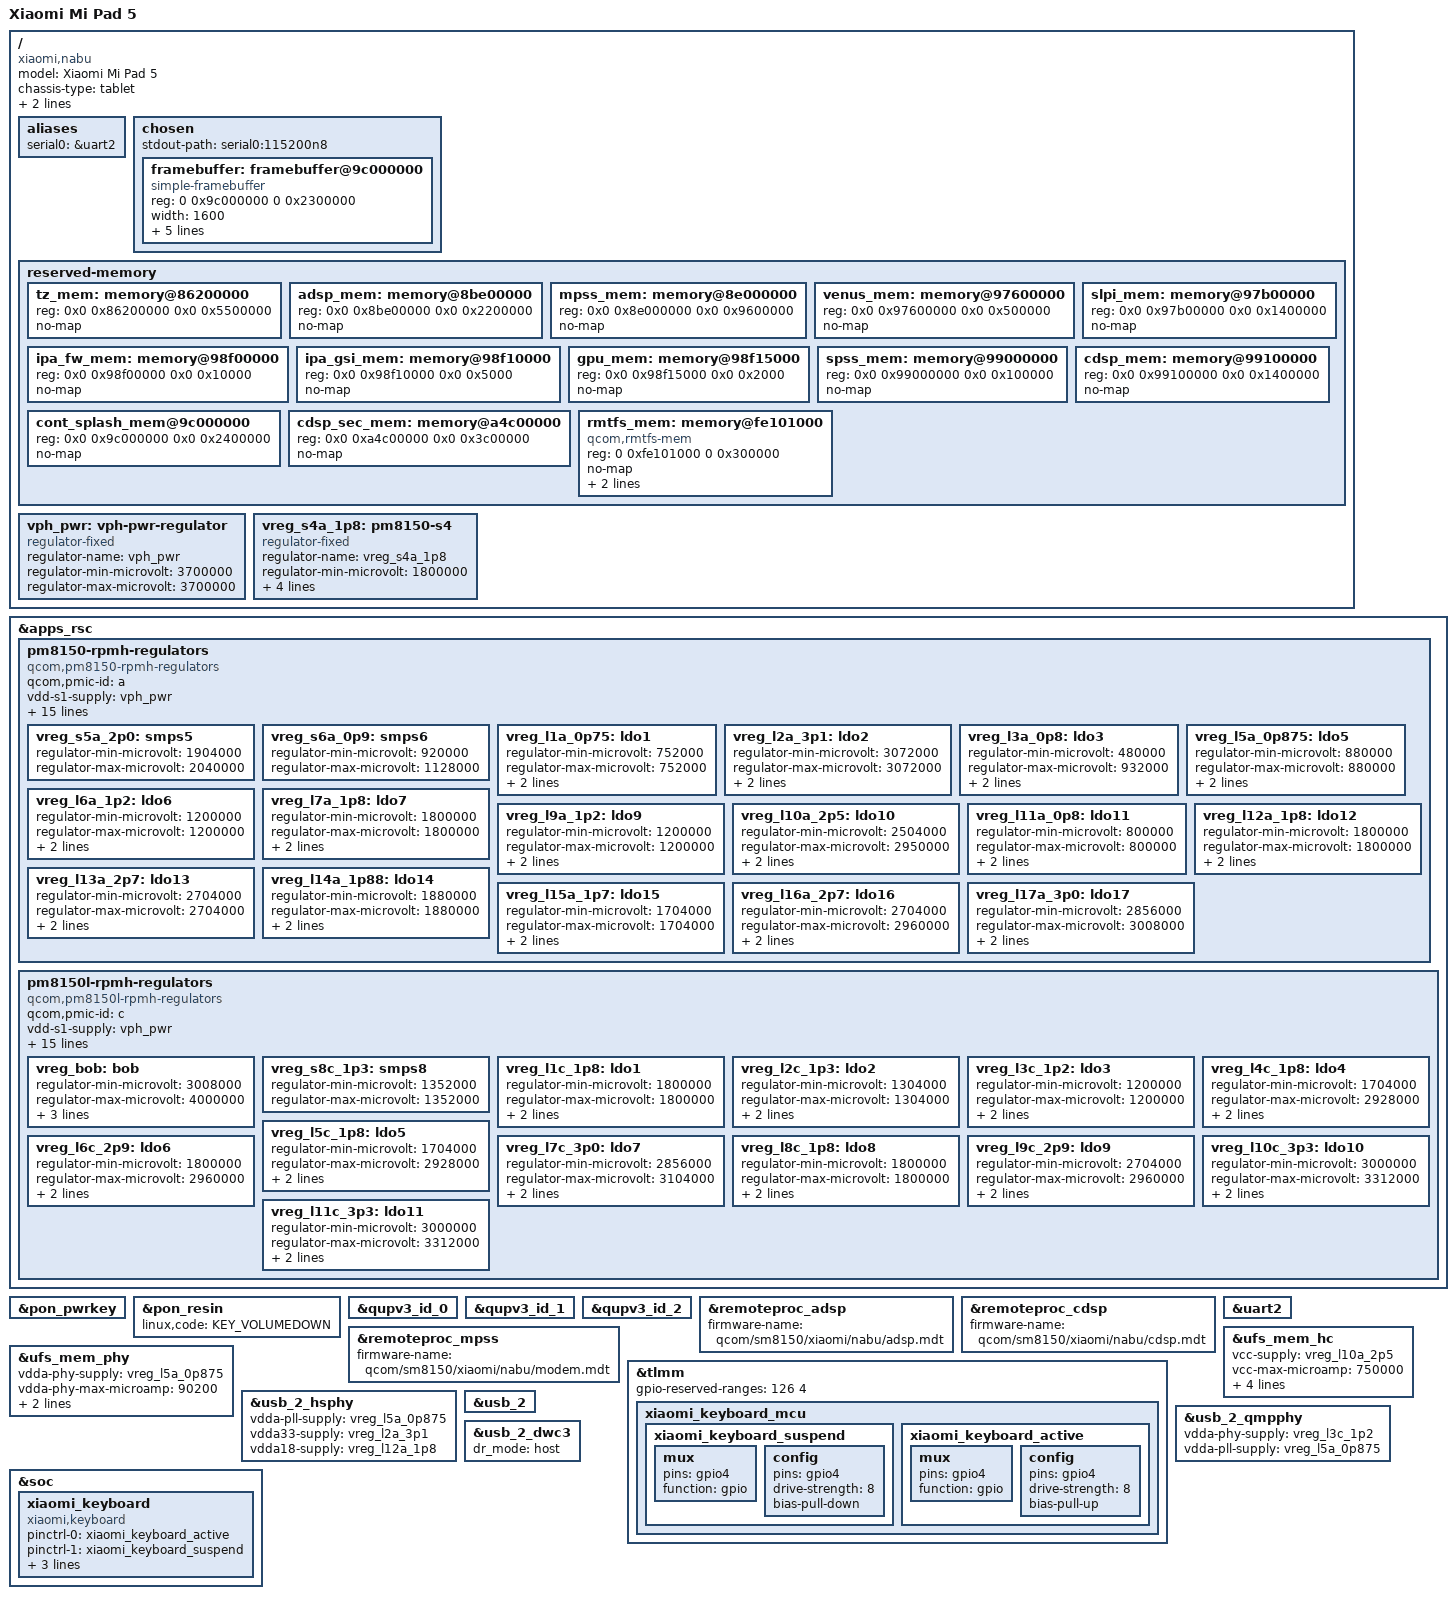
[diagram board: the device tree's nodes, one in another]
// SPDX-License-Identifier: BSD-3-Clause
/*
 * Copyright (c) 2017-2019, The Linux Foundation. All rights reserved.
 * Copyright (c) 2019, Linaro Limited
 */

/dts-v1/;

#include <dt-bindings/regulator/qcom,rpmh-regulator.h>
#include <dt-bindings/gpio/gpio.h>
#include <dt-bindings/usb/pd.h>
#include <dt-bindings/phy/phy.h>
#include "sm8150.dtsi"
#include "pm8150.dtsi"
#include "pm8150b.dtsi"
#include "pm8150l.dtsi"

/delete-node/ &tz_mem;
/delete-node/ &cdsp_mem;
/delete-node/ &gpu_mem;
/delete-node/ &ipa_fw_mem;
/delete-node/ &ipa_gsi_mem;
/delete-node/ &adsp_mem;
/delete-node/ &mpss_mem;
/delete-node/ &slpi_mem;
/delete-node/ &spss_mem;
/delete-node/ &venus_mem;
/delete-node/ &rmtfs_mem;
/*
 * delete node mdss and dispcc if
 * use simple-framebuffer
 */
/delete-node/ &mdss;
/delete-node/ &dispcc;

/ {
	model = "Xiaomi Mi Pad 5";
	compatible = "xiaomi,nabu", "qcom,sm8150";
	chassis-type = "tablet";
	qcom,msm-id = <339 0x20000>;
	qcom,board-id = <48 0>;

	aliases {
		serial0 = &uart2;
	};

	chosen {
		#address-cells = <2>;
		#size-cells = <2>;
		ranges;

		stdout-path = "serial0:115200n8";

		framebuffer: framebuffer@9c000000 {
		compatible = "simple-framebuffer";
			reg = <0 0x9c000000 0 0x2300000>;
			width = <1600>;
			height = <2560>;
			stride = <(1600 * 4)>;
			format = "a8r8g8b8";
			/*
			* That's (going to be) a lot of clocks, but it's necessary due
			* to unused clk cleanup & no panel driver yet (& no dispcc either)..
			*/
			clocks = <&gcc GCC_DISP_HF_AXI_CLK>,
					<&gcc GCC_DISP_SF_AXI_CLK>;
		};
	};

	reserved-memory {
		#address-cells = <2>;
		#size-cells = <2>;
		ranges;

		tz_mem: memory@86200000 {
			reg = <0x0 0x86200000 0x0 0x5500000>;
			no-map;
		};

		adsp_mem: memory@8be00000 {
			reg = <0x0 0x8be00000 0x0 0x2200000>;
			no-map;
		};

		mpss_mem: memory@8e000000 {
			reg = <0x0 0x8e000000 0x0 0x9600000>;
			no-map;
		};

		venus_mem: memory@97600000 {
			reg = <0x0 0x97600000 0x0 0x500000>;
			no-map;
		};

		slpi_mem: memory@97b00000 {
			reg = <0x0 0x97b00000 0x0 0x1400000>;
			no-map;
		};

		ipa_fw_mem: memory@98f00000 {
			reg = <0x0 0x98f00000 0x0 0x10000>;
			no-map;
		};

		ipa_gsi_mem: memory@98f10000 {
			reg = <0x0 0x98f10000 0x0 0x5000>;
			no-map;
		};

		gpu_mem: memory@98f15000 {
			reg = <0x0 0x98f15000 0x0 0x2000>;
			no-map;
		};

		spss_mem: memory@99000000 {
			reg = <0x0 0x99000000 0x0 0x100000>;
			no-map;
		};

		cdsp_mem: memory@99100000 {
			reg = <0x0 0x99100000 0x0 0x1400000>;
			no-map;
		};

		cont_splash_mem@9c000000 {
			reg = <0x0 0x9c000000 0x0 0x2400000>;
			no-map;
		};

		cdsp_sec_mem: memory@a4c00000 {
			reg = <0x0 0xa4c00000 0x0 0x3c00000>;
			no-map;
		};

		rmtfs_mem: memory@fe101000 {
			compatible = "qcom,rmtfs-mem";
			reg = <0 0xfe101000 0 0x300000>;
			no-map;

			qcom,client-id = <1>;
			qcom,vmid = <15>;
		};
	};

	vph_pwr: vph-pwr-regulator {
		compatible = "regulator-fixed";
		regulator-name = "vph_pwr";
		regulator-min-microvolt = <3700000>;
		regulator-max-microvolt = <3700000>;
	};

	/*
	 * Apparently RPMh does not provide support for PM8150 S4 because it
	 * is always-on; model it as a fixed regulator.
	 */
	vreg_s4a_1p8: pm8150-s4 {
		compatible = "regulator-fixed";
		regulator-name = "vreg_s4a_1p8";

		regulator-min-microvolt = <1800000>;
		regulator-max-microvolt = <1800000>;

		regulator-always-on;
		regulator-boot-on;

		vin-supply = <&vph_pwr>;
	};
};

&apps_rsc {
	pm8150-rpmh-regulators {
		compatible = "qcom,pm8150-rpmh-regulators";
		qcom,pmic-id = "a";

		vdd-s1-supply = <&vph_pwr>;
		vdd-s2-supply = <&vph_pwr>;
		vdd-s3-supply = <&vph_pwr>;
		vdd-s4-supply = <&vph_pwr>;
		vdd-s5-supply = <&vph_pwr>;
		vdd-s6-supply = <&vph_pwr>;
		vdd-s7-supply = <&vph_pwr>;
		vdd-s8-supply = <&vph_pwr>;
		vdd-s9-supply = <&vph_pwr>;
		vdd-s10-supply = <&vph_pwr>;

		vdd-l1-l8-l11-supply = <&vreg_s6a_0p9>;
		vdd-l2-l10-supply = <&vreg_bob>;
		vdd-l3-l4-l5-l18-supply = <&vreg_s6a_0p9>;
		vdd-l6-l9-supply = <&vreg_s8c_1p3>;
		vdd-l7-l12-l14-l15-supply = <&vreg_s5a_2p0>;
		vdd-l13-l16-l17-supply = <&vreg_bob>;

		vreg_s5a_2p0: smps5 {
			regulator-min-microvolt = <1904000>;
			regulator-max-microvolt = <2040000>;
		};

		vreg_s6a_0p9: smps6 {
			regulator-min-microvolt = <920000>;
			regulator-max-microvolt = <1128000>;
		};

		vreg_l1a_0p75: ldo1 {
			regulator-min-microvolt = <752000>;
			regulator-max-microvolt = <752000>;
			regulator-initial-mode = <RPMH_REGULATOR_MODE_HPM>;
		};

		vreg_l2a_3p1: ldo2 {
			regulator-min-microvolt = <3072000>;
			regulator-max-microvolt = <3072000>;
			regulator-initial-mode = <RPMH_REGULATOR_MODE_HPM>;
		};

		vreg_l3a_0p8: ldo3 {
			regulator-min-microvolt = <480000>;
			regulator-max-microvolt = <932000>;
			regulator-initial-mode = <RPMH_REGULATOR_MODE_HPM>;
		};

		vreg_l5a_0p875: ldo5 {
			regulator-min-microvolt = <880000>;
			regulator-max-microvolt = <880000>;
			regulator-initial-mode = <RPMH_REGULATOR_MODE_HPM>;
		};

		vreg_l6a_1p2: ldo6 {
			regulator-min-microvolt = <1200000>;
			regulator-max-microvolt = <1200000>;
			regulator-initial-mode = <RPMH_REGULATOR_MODE_HPM>;
		};

		vreg_l7a_1p8: ldo7 {
			regulator-min-microvolt = <1800000>;
			regulator-max-microvolt = <1800000>;
			regulator-initial-mode = <RPMH_REGULATOR_MODE_HPM>;
		};

		vreg_l9a_1p2: ldo9 {
			regulator-min-microvolt = <1200000>;
			regulator-max-microvolt = <1200000>;
			regulator-initial-mode = <RPMH_REGULATOR_MODE_HPM>;
		};

		vreg_l10a_2p5: ldo10 {
			regulator-min-microvolt = <2504000>;
			regulator-max-microvolt = <2950000>;
			regulator-initial-mode = <RPMH_REGULATOR_MODE_HPM>;
		};

		vreg_l11a_0p8: ldo11 {
			regulator-min-microvolt = <800000>;
			regulator-max-microvolt = <800000>;
			regulator-initial-mode = <RPMH_REGULATOR_MODE_HPM>;
		};

		vreg_l12a_1p8: ldo12 {
			regulator-min-microvolt = <1800000>;
			regulator-max-microvolt = <1800000>;
			regulator-initial-mode = <RPMH_REGULATOR_MODE_HPM>;
		};

		vreg_l13a_2p7: ldo13 {
			regulator-min-microvolt = <2704000>;
			regulator-max-microvolt = <2704000>;
			regulator-initial-mode = <RPMH_REGULATOR_MODE_HPM>;
		};

		vreg_l14a_1p88: ldo14 {
			regulator-min-microvolt = <1880000>;
			regulator-max-microvolt = <1880000>;
			regulator-initial-mode = <RPMH_REGULATOR_MODE_HPM>;
		};

		vreg_l15a_1p7: ldo15 {
			regulator-min-microvolt = <1704000>;
			regulator-max-microvolt = <1704000>;
			regulator-initial-mode = <RPMH_REGULATOR_MODE_HPM>;
		};

		vreg_l16a_2p7: ldo16 {
			regulator-min-microvolt = <2704000>;
			regulator-max-microvolt = <2960000>;
			regulator-initial-mode = <RPMH_REGULATOR_MODE_HPM>;
		};

		vreg_l17a_3p0: ldo17 {
			regulator-min-microvolt = <2856000>;
			regulator-max-microvolt = <3008000>;
			regulator-initial-mode = <RPMH_REGULATOR_MODE_HPM>;
		};
	};

	pm8150l-rpmh-regulators {
		compatible = "qcom,pm8150l-rpmh-regulators";
		qcom,pmic-id = "c";

		vdd-s1-supply = <&vph_pwr>;
		vdd-s2-supply = <&vph_pwr>;
		vdd-s3-supply = <&vph_pwr>;
		vdd-s4-supply = <&vph_pwr>;
		vdd-s5-supply = <&vph_pwr>;
		vdd-s6-supply = <&vph_pwr>;
		vdd-s7-supply = <&vph_pwr>;
		vdd-s8-supply = <&vph_pwr>;

		vdd-l1-l8-supply = <&vreg_s4a_1p8>;
		vdd-l2-l3-supply = <&vreg_s8c_1p3>;
		vdd-l4-l5-l6-supply = <&vreg_bob>;
		vdd-l7-l11-supply = <&vreg_bob>;
		vdd-l9-l10-supply = <&vreg_bob>;

		vdd-bob-supply = <&vph_pwr>;
		vdd-flash-supply = <&vreg_bob>;
		vdd-rgb-supply = <&vreg_bob>;

		vreg_bob: bob {
			regulator-min-microvolt = <3008000>;
			regulator-max-microvolt = <4000000>;
			regulator-initial-mode = <RPMH_REGULATOR_MODE_AUTO>;
			regulator-allow-bypass;
		};

		vreg_s8c_1p3: smps8 {
			regulator-min-microvolt = <1352000>;
			regulator-max-microvolt = <1352000>;
		};

		vreg_l1c_1p8: ldo1 {
			regulator-min-microvolt = <1800000>;
			regulator-max-microvolt = <1800000>;
			regulator-initial-mode = <RPMH_REGULATOR_MODE_HPM>;
		};

		vreg_l2c_1p3: ldo2 {
			regulator-min-microvolt = <1304000>;
			regulator-max-microvolt = <1304000>;
			regulator-initial-mode = <RPMH_REGULATOR_MODE_HPM>;
		};

		vreg_l3c_1p2: ldo3 {
			regulator-min-microvolt = <1200000>;
			regulator-max-microvolt = <1200000>;
			regulator-initial-mode = <RPMH_REGULATOR_MODE_HPM>;
		};

		vreg_l4c_1p8: ldo4 {
			regulator-min-microvolt = <1704000>;
			regulator-max-microvolt = <2928000>;
			regulator-initial-mode = <RPMH_REGULATOR_MODE_HPM>;
		};

		vreg_l5c_1p8: ldo5 {
			regulator-min-microvolt = <1704000>;
			regulator-max-microvolt = <2928000>;
			regulator-initial-mode = <RPMH_REGULATOR_MODE_HPM>;
		};

		vreg_l6c_2p9: ldo6 {
			regulator-min-microvolt = <1800000>;
			regulator-max-microvolt = <2960000>;
			regulator-initial-mode = <RPMH_REGULATOR_MODE_HPM>;
		};

		vreg_l7c_3p0: ldo7 {
			regulator-min-microvolt = <2856000>;
			regulator-max-microvolt = <3104000>;
			regulator-initial-mode = <RPMH_REGULATOR_MODE_HPM>;
		};

		vreg_l8c_1p8: ldo8 {
			regulator-min-microvolt = <1800000>;
			regulator-max-microvolt = <1800000>;
			regulator-initial-mode = <RPMH_REGULATOR_MODE_HPM>;
		};

		vreg_l9c_2p9: ldo9 {
			regulator-min-microvolt = <2704000>;
			regulator-max-microvolt = <2960000>;
			regulator-initial-mode = <RPMH_REGULATOR_MODE_HPM>;
		};

		vreg_l10c_3p3: ldo10 {
			regulator-min-microvolt = <3000000>;
			regulator-max-microvolt = <3312000>;
			regulator-initial-mode = <RPMH_REGULATOR_MODE_HPM>;
		};

		vreg_l11c_3p3: ldo11 {
			regulator-min-microvolt = <3000000>;
			regulator-max-microvolt = <3312000>;
			regulator-initial-mode = <RPMH_REGULATOR_MODE_HPM>;
		};
	};

	/* PM8009 is not present on these boards, even if downstream sources suggest so. */
};

&pon_pwrkey {
	status = "okay";
};

&pon_resin {
	status = "okay";

	linux,code = <KEY_VOLUMEDOWN>;
};

&qupv3_id_0 {
	status = "okay";
};

&qupv3_id_1 {
	status = "okay";
};

&qupv3_id_2 {
	status = "okay";
};

&remoteproc_adsp {
	status = "okay";
	firmware-name = "qcom/sm8150/xiaomi/nabu/adsp.mdt";
};

&remoteproc_cdsp {
	status = "okay";
	firmware-name = "qcom/sm8150/xiaomi/nabu/cdsp.mdt";
};

&remoteproc_mpss {
	status = "okay";
	firmware-name = "qcom/sm8150/xiaomi/nabu/modem.mdt";
};

&tlmm {
	gpio-reserved-ranges = <126 4>;

	xiaomi_keyboard_mcu {
		xiaomi_keyboard_suspend: xiaomi_keyboard_suspend {
			mux {
				pins = "gpio4";
				function = "gpio";
			};

			config {
				pins = "gpio4";
				drive-strength = <8>;
				bias-pull-down;
			};
		};

		xiaomi_keyboard_active: xiaomi_keyboard_active {
			mux {
				pins = "gpio4";
				function = "gpio";
			};

			config {
				pins = "gpio4";
				drive-strength = <8>;
				bias-pull-up;
			};
		};
	};
};

&uart2 {
	status = "okay";
};

&ufs_mem_hc {
	status = "okay";

	vcc-supply = <&vreg_l10a_2p5>;
	vcc-max-microamp = <750000>;
	vccq-supply = <&vreg_l9a_1p2>;
	vccq-max-microamp = <700000>;
	vccq2-supply = <&vreg_s4a_1p8>;
	vccq2-max-microamp = <750000>;
};

&ufs_mem_phy {
	status = "okay";

	vdda-phy-supply = <&vreg_l5a_0p875>;
	vdda-phy-max-microamp = <90200>;
	vdda-pll-supply = <&vreg_l3c_1p2>;
	vdda-pll-max-microamp = <19000>;
};

&usb_2_hsphy {
	status = "okay";
	vdda-pll-supply = <&vreg_l5a_0p875>;
	vdda33-supply = <&vreg_l2a_3p1>;
	vdda18-supply = <&vreg_l12a_1p8>;
};

&usb_2_qmpphy {
	status = "okay";
	vdda-phy-supply = <&vreg_l3c_1p2>;
	vdda-pll-supply = <&vreg_l5a_0p875>;
};

&usb_2 {
	status = "okay";
};

&usb_2_dwc3 {
	dr_mode = "host";
};

&soc {
	xiaomi_keyboard {
		compatible = "xiaomi,keyboard";

		pinctrl-names = "pm_kb_active", "pm_kb_suspend";
		pinctrl-0 = <&xiaomi_keyboard_active>;
		pinctrl-1 = <&xiaomi_keyboard_suspend>;

		xiaomi-keyboard,rst-gpio = <&tlmm 49 0x00>;
		xiaomi-keyboard,in-irq-gpio = <&tlmm 41 0x2001>;
		xiaomi-keyboard,vdd-gpio = <&tlmm 82 0x00>;
		status = "ok";
	};
};

